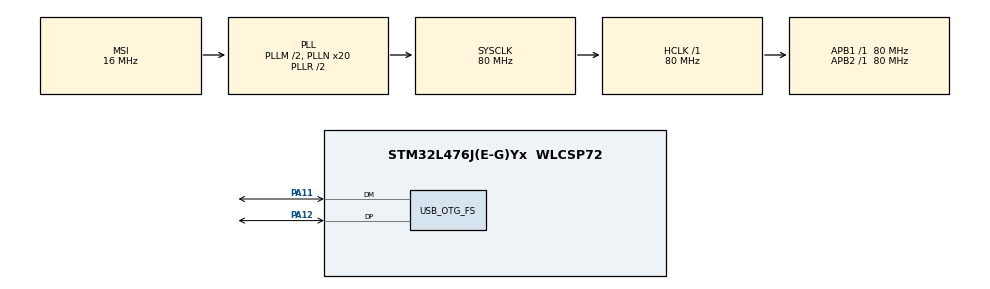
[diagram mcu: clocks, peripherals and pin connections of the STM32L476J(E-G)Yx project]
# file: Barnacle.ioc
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Mcu.Family=STM32L4
Mcu.Name=STM32L476J(E-G)Yx
Mcu.Package=WLCSP72
NVIC.OTG_FS_IRQn=true\:0\:0\:false\:false\:true
NVIC.PriorityGroup=NVIC_PRIORITYGROUP_4
PA11.Mode=Device_Only
PA11.Signal=USB_OTG_FS_DM
PA12.Mode=Device_Only
PA12.Signal=USB_OTG_FS_DP
PA13.Mode=Serial_Wire
PA13.Signal=SYS_JTMS-SWDIO
PA14.Mode=Serial_Wire
PA14.Signal=SYS_JTCK-SWCLK
ProjectManager.HeapSize=0x1000
ProjectManager.StackSize=0x1000
ProjectManager.TargetToolchain=TrueSTUDIO
RCC.ADCFreq_Value=48000000
RCC.AHBFreq_Value=80000000
RCC.APB1Freq_Value=80000000
RCC.APB1TimFreq_Value=80000000
RCC.APB2Freq_Value=80000000
RCC.APB2TimFreq_Value=80000000
RCC.CortexFreq_Value=80000000
RCC.HCLKFreq_Value=80000000
RCC.HSE_VALUE=8000000
RCC.HSI_VALUE=16000000
RCC.MSIClockRange=RCC_MSIRANGE_8
RCC.MSI_VALUE=16000000
RCC.PLLM=2
RCC.PLLN=20
RCC.PLLSAI1N=12
RCC.SYSCLKFreq_VALUE=80000000
RCC.SYSCLKSource=RCC_SYSCLKSOURCE_PLLCLK
RCC.USBFreq_Value=48000000
RCC.VCOOutputFreq_Value=160000000
USB_DEVICE.CLASS_NAME_FS=DFU
USB_DEVICE.VirtualModeFS=Dfu_FS
USB_OTG_FS.VirtualMode=Device_Only
USB_OTG_FS.vbus_sensing_enable=DISABLE
VP_RNG_VS_RNG.Mode=RNG_Activate
VP_RTC_VS_RTC_Activate.Mode=RTC_Enabled
VP_RTC_VS_RTC_Calendar.Mode=RTC_Calendar
VP_USB_DEVICE_VS_USB_DEVICE_DFU_FS.Mode=DFU_FS
board=Barnacle

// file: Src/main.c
/**
  ******************************************************************************
  * File Name          : main.c
  * Description        : Main program body
  ******************************************************************************
  *
  * Copyright (c) 2017 STMicroelectronics International N.V.
  * All rights reserved.
  *
  * Redistribution and use in source and binary forms, with or without
  * modification, are permitted, provided that the following conditions are met:
  *
  * 1. Redistribution of source code must retain the above copyright notice,
  *    this list of conditions and the following disclaimer.
  * 2. Redistributions in binary form must reproduce the above copyright notice,
  *    this list of conditions and the following disclaimer in the documentation
  *    and/or other materials provided with the distribution.
  * 3. Neither the name of STMicroelectronics nor the names of other
  *    contributors to this software may be used to endorse or promote products
  *    derived from this software without specific written permission.
  * 4. This software, including modifications and/or derivative works of this
  *    software, must execute solely and exclusively on microcontroller or
  *    microprocessor devices manufactured by or for STMicroelectronics.
  * 5. Redistribution and use of this software other than as permitted under
  *    this license is void and will automatically terminate your rights under
  *    this license.
  *
  * THIS SOFTWARE IS PROVIDED BY STMICROELECTRONICS AND CONTRIBUTORS "AS IS"
  * AND ANY EXPRESS, IMPLIED OR STATUTORY WARRANTIES, INCLUDING, BUT NOT
  * LIMITED TO, THE IMPLIED WARRANTIES OF MERCHANTABILITY, FITNESS FOR A
  * PARTICULAR PURPOSE AND NON-INFRINGEMENT OF THIRD PARTY INTELLECTUAL PROPERTY
  * RIGHTS ARE DISCLAIMED TO THE FULLEST EXTENT PERMITTED BY LAW. IN NO EVENT
  * SHALL STMICROELECTRONICS OR CONTRIBUTORS BE LIABLE FOR ANY DIRECT, INDIRECT,
  * INCIDENTAL, SPECIAL, EXEMPLARY, OR CONSEQUENTIAL DAMAGES (INCLUDING, BUT NOT
  * LIMITED TO, PROCUREMENT OF SUBSTITUTE GOODS OR SERVICES; LOSS OF USE, DATA,
  * OR PROFITS; OR BUSINESS INTERRUPTION) HOWEVER CAUSED AND ON ANY THEORY OF
  * LIABILITY, WHETHER IN CONTRACT, STRICT LIABILITY, OR TORT (INCLUDING
  * NEGLIGENCE OR OTHERWISE) ARISING IN ANY WAY OUT OF THE USE OF THIS SOFTWARE,
  * EVEN IF ADVISED OF THE POSSIBILITY OF SUCH DAMAGE.
  *
  ******************************************************************************
  */
#include "main.h"
#include "stm32l4xx_hal.h"
#include "usb_device.h"
#include "Barnacle.h"

RNG_HandleTypeDef hrng;

RTC_HandleTypeDef hrtc;

/* USER CODE BEGIN PV */
/* Private variables ---------------------------------------------------------*/
volatile uint8_t DFU_UsrStrDescr_requested = 0;
/* USER CODE END PV */

void SystemClock_Config(void);
void Error_Handler(void);
static void MX_GPIO_Init(void);
static void MX_RTC_Init(void);
static void MX_RNG_Init(void);

/* USER CODE BEGIN PFP */
/* Private function prototypes -----------------------------------------------*/

/* USER CODE END PFP */

int main(void)
{

  /* MCU Configuration----------------------------------------------------------*/

  /* Reset of all peripherals, Initializes the Flash interface and the Systick. */
  HAL_Init();

  /* Configure the system clock */
  SystemClock_Config();

  /* Initialize all configured peripherals */
  MX_GPIO_Init();
  MX_RTC_Init();
  MX_USB_DEVICE_Init();
  MX_RNG_Init();

  /* USER CODE BEGIN 2 */
  fprintf(stderr, "Barnacle\r\n");
  BarnacleInitialProvision();
  BarnacleDumpCertBag();

  // If DFU connected we service that
  HAL_Delay(200);
  if(DFU_UsrStrDescr_requested)
  {
      fprintf(stderr, "INFO: DFU connected\r\n");
  }
  else
  {
      MX_USB_DEVICE_DeInit();
  }

  for(;;);

  // The point of no return: Launch the agent
  fprintf(stderr, "INFO: Preparing for launching agent '%s'...\r\n", AgentHdr.s.sign.agent.name);
  // Release the clock source
  HAL_RCC_DeInit();
  // Release the HAL
  HAL_DeInit();
  // Redirect the vector table to the agent vector table
  SCB->VTOR = ((uint32_t)&AgentHdr) + AgentHdr.s.sign.agent.offset;
  // Wipe all accessible RAM to make sure we didn't leave anything behind
  memset((void*)RAMWIPESTART1, 0x00, RAMWIPESIZE1);
  memset((void*)RAMWIPESTART2, 0x00, RAMWIPESIZE2);
  // Set the stack pointer to where the agent expects it
  __set_MSP(*((uint32_t*)(((uint32_t)&AgentHdr) + AgentHdr.s.sign.agent.offset)));
  // Jump into the abyss
  ((void (*)(void)) *((uint32_t*)(((uint32_t)&AgentHdr) + AgentHdr.s.sign.agent.offset + sizeof(uint32_t))))();
  // We will never return from this call!!

  /* USER CODE END 2 */

  /* Infinite loop */
  while (1)
  {

  /* USER CODE BEGIN 3 */
  fprintf(stderr, "ERROR: How the hell did we get here?!?\r\n");
  HAL_Delay(1000);

  }
  /* USER CODE END 3 */

}

/** System Clock Configuration
*/
void SystemClock_Config(void)
{

  RCC_OscInitTypeDef RCC_OscInitStruct;
  RCC_ClkInitTypeDef RCC_ClkInitStruct;
  RCC_PeriphCLKInitTypeDef PeriphClkInit;

    /**Initializes the CPU, AHB and APB busses clocks
    */
  RCC_OscInitStruct.OscillatorType = RCC_OSCILLATORTYPE_LSI|RCC_OSCILLATORTYPE_MSI;
  RCC_OscInitStruct.LSIState = RCC_LSI_ON;
  RCC_OscInitStruct.MSIState = RCC_MSI_ON;
  RCC_OscInitStruct.MSICalibrationValue = 0;
  RCC_OscInitStruct.MSIClockRange = RCC_MSIRANGE_8;
  RCC_OscInitStruct.PLL.PLLState = RCC_PLL_ON;
  RCC_OscInitStruct.PLL.PLLSource = RCC_PLLSOURCE_MSI;
  RCC_OscInitStruct.PLL.PLLM = 2;
  RCC_OscInitStruct.PLL.PLLN = 20;
  RCC_OscInitStruct.PLL.PLLP = RCC_PLLP_DIV7;
  RCC_OscInitStruct.PLL.PLLQ = RCC_PLLQ_DIV2;
  RCC_OscInitStruct.PLL.PLLR = RCC_PLLR_DIV2;
  if (HAL_RCC_OscConfig(&RCC_OscInitStruct) != HAL_OK)
  {
    Error_Handler();
  }

    /**Initializes the CPU, AHB and APB busses clocks
    */
  RCC_ClkInitStruct.ClockType = RCC_CLOCKTYPE_HCLK|RCC_CLOCKTYPE_SYSCLK
                              |RCC_CLOCKTYPE_PCLK1|RCC_CLOCKTYPE_PCLK2;
  RCC_ClkInitStruct.SYSCLKSource = RCC_SYSCLKSOURCE_PLLCLK;
  RCC_ClkInitStruct.AHBCLKDivider = RCC_SYSCLK_DIV1;
  RCC_ClkInitStruct.APB1CLKDivider = RCC_HCLK_DIV1;
  RCC_ClkInitStruct.APB2CLKDivider = RCC_HCLK_DIV1;

  if (HAL_RCC_ClockConfig(&RCC_ClkInitStruct, FLASH_LATENCY_4) != HAL_OK)
  {
    Error_Handler();
  }

  PeriphClkInit.PeriphClockSelection = RCC_PERIPHCLK_RTC|RCC_PERIPHCLK_USB
                              |RCC_PERIPHCLK_RNG;
  PeriphClkInit.RTCClockSelection = RCC_RTCCLKSOURCE_LSI;
  PeriphClkInit.UsbClockSelection = RCC_USBCLKSOURCE_PLLSAI1;
  PeriphClkInit.RngClockSelection = RCC_RNGCLKSOURCE_PLLSAI1;
  PeriphClkInit.PLLSAI1.PLLSAI1Source = RCC_PLLSOURCE_MSI;
  PeriphClkInit.PLLSAI1.PLLSAI1M = 2;
  PeriphClkInit.PLLSAI1.PLLSAI1N = 12;
  PeriphClkInit.PLLSAI1.PLLSAI1P = RCC_PLLP_DIV7;
  PeriphClkInit.PLLSAI1.PLLSAI1Q = RCC_PLLQ_DIV2;
  PeriphClkInit.PLLSAI1.PLLSAI1R = RCC_PLLR_DIV2;
  PeriphClkInit.PLLSAI1.PLLSAI1ClockOut = RCC_PLLSAI1_48M2CLK;
  if (HAL_RCCEx_PeriphCLKConfig(&PeriphClkInit) != HAL_OK)
  {
    Error_Handler();
  }

    /**Configure the main internal regulator output voltage
    */
  if (HAL_PWREx_ControlVoltageScaling(PWR_REGULATOR_VOLTAGE_SCALE1) != HAL_OK)
  {
    Error_Handler();
  }

    /**Configure the Systick interrupt time
    */
  HAL_SYSTICK_Config(HAL_RCC_GetHCLKFreq()/1000);

    /**Configure the Systick
    */
  HAL_SYSTICK_CLKSourceConfig(SYSTICK_CLKSOURCE_HCLK);

  /* SysTick_IRQn interrupt configuration */
  HAL_NVIC_SetPriority(SysTick_IRQn, 0, 0);
}

/* RNG init function */
static void MX_RNG_Init(void)
{

  hrng.Instance = RNG;
  if (HAL_RNG_Init(&hrng) != HAL_OK)
  {
    Error_Handler();
  }

}

/* RTC init function */
static void MX_RTC_Init(void)
{

  RTC_TimeTypeDef sTime;
  RTC_DateTypeDef sDate;

    /**Initialize RTC Only
    */
  hrtc.Instance = RTC;
  hrtc.Init.HourFormat = RTC_HOURFORMAT_24;
  hrtc.Init.AsynchPrediv = 127;
  hrtc.Init.SynchPrediv = 255;
  hrtc.Init.OutPut = RTC_OUTPUT_DISABLE;
  hrtc.Init.OutPutRemap = RTC_OUTPUT_REMAP_NONE;
  hrtc.Init.OutPutPolarity = RTC_OUTPUT_POLARITY_HIGH;
  hrtc.Init.OutPutType = RTC_OUTPUT_TYPE_OPENDRAIN;
  if (HAL_RTC_Init(&hrtc) != HAL_OK)
  {
    Error_Handler();
  }

    /**Initialize RTC and set the Time and Date
    */
  sTime.Hours = 0x0;
  sTime.Minutes = 0x0;
  sTime.Seconds = 0x0;
  sTime.DayLightSaving = RTC_DAYLIGHTSAVING_NONE;
  sTime.StoreOperation = RTC_STOREOPERATION_RESET;
  if (HAL_RTC_SetTime(&hrtc, &sTime, RTC_FORMAT_BCD) != HAL_OK)
  {
    Error_Handler();
  }

  sDate.WeekDay = RTC_WEEKDAY_MONDAY;
  sDate.Month = RTC_MONTH_JANUARY;
  sDate.Date = 0x1;
  sDate.Year = 0x0;

  if (HAL_RTC_SetDate(&hrtc, &sDate, RTC_FORMAT_BCD) != HAL_OK)
  {
    Error_Handler();
  }

}

/** Configure pins as
        * Analog
        * Input
        * Output
        * EVENT_OUT
        * EXTI
*/
static void MX_GPIO_Init(void)
{

  /* GPIO Ports Clock Enable */
  __HAL_RCC_GPIOA_CLK_ENABLE();

}

void Error_Handler(void)
{
  while(1)
  {
  }
}

/************************ (C) COPYRIGHT STMicroelectronics *****END OF FILE****/
